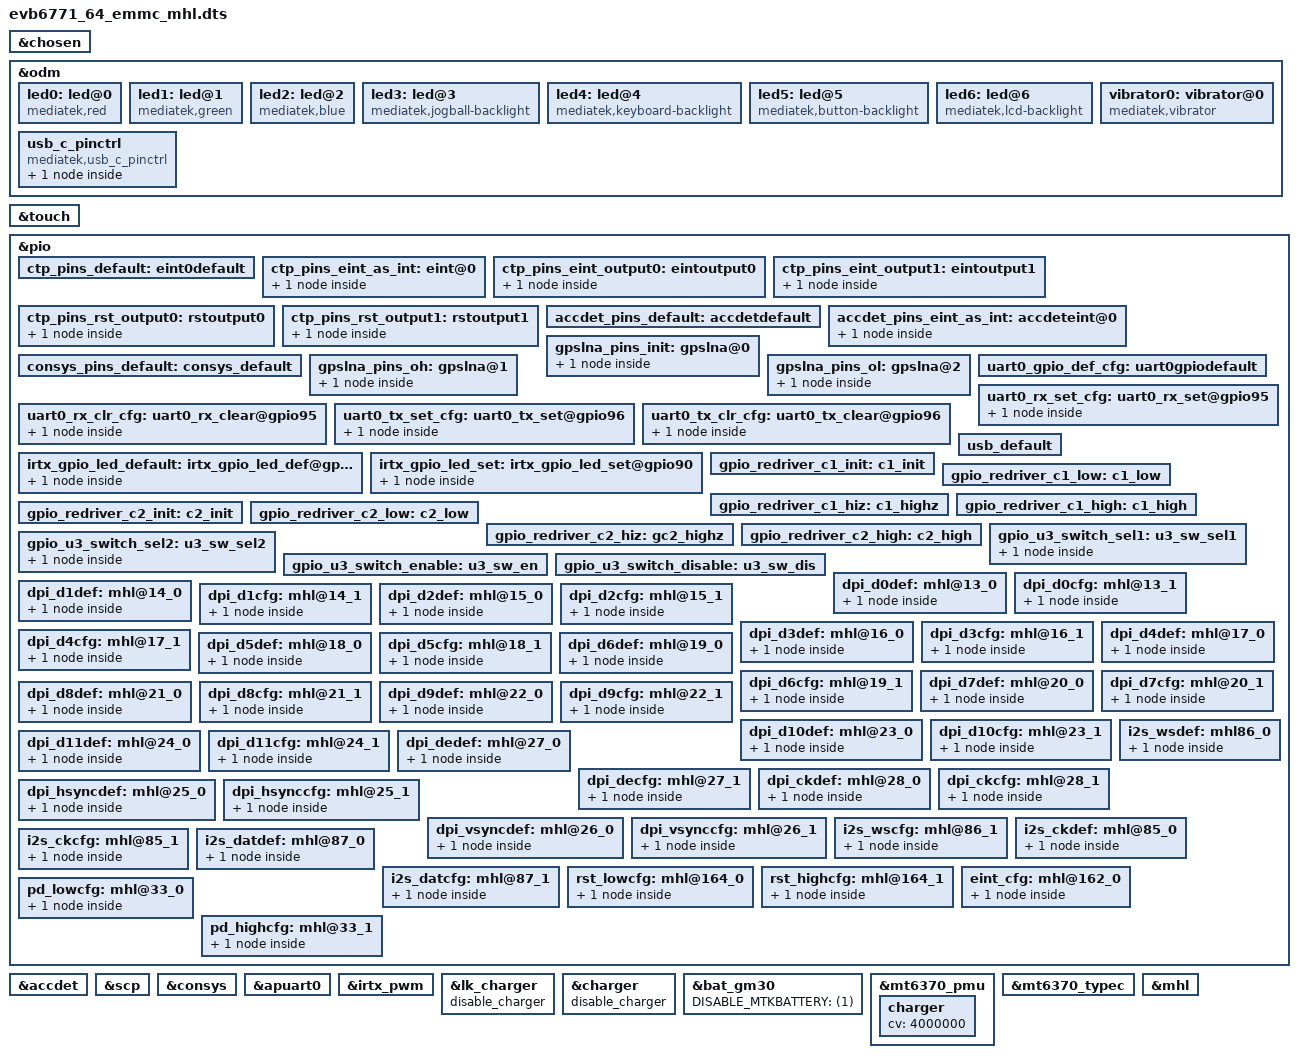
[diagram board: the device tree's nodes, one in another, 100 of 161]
/dts-v1/;
/plugin/;
#include <dt-bindings/interrupt-controller/irq.h>
#include <dt-bindings/interrupt-controller/arm-gic.h>
#include <dt-bindings/pinctrl/mt6771-pinfunc.h>

/* chosen */
&chosen {
	bootargs = "console=tty0 console=ttyMT0,921600n1 root=/dev/ram \
initrd=0x55000000,0x3000000 loglevel=8 \
androidboot.selinux=permissive androidboot.hardware=mt6771 \
initcall_debug=1";
	/* fpga may has no lk, we need to specify display info here */
	/* fb buffer is reserved using this dts by memory node above */

	atag,videolfb-fb_base_l = <0x5e605000>;
	atag,videolfb-fb_base_h = <0x0>;
	atag,videolfb-islcmfound = <1>;
	atag,videolfb-islcm_inited = <0>;
	atag,videolfb-fps= <6000>;
	atag,videolfb-vramSize= <0x017bb000>;
	atag,videolfb-lcmname= "nt35595_fhd_dsi_cmd_truly_nt50358_drv";
};

&odm {
	led0:led@0 {
		compatible = "mediatek,red";
		led_mode = <0>;
		data = <1>;
		pwm_config = <0 0 0 0 0>;
	};
	led1:led@1 {
		compatible = "mediatek,green";
		led_mode = <0>;
		data = <1>;
		pwm_config = <0 0 0 0 0>;
	};
	led2:led@2 {
		compatible = "mediatek,blue";
		led_mode = <0>;
		data = <1>;
		pwm_config = <0 0 0 0 0>;
	};
	led3:led@3 {
		compatible = "mediatek,jogball-backlight";
		led_mode = <0>;
		data = <1>;
		pwm_config = <0 0 0 0 0>;
	};
	led4:led@4 {
		compatible = "mediatek,keyboard-backlight";
		led_mode = <0>;
		data = <1>;
		pwm_config = <0 0 0 0 0>;
	};
	led5:led@5 {
		compatible = "mediatek,button-backlight";
		led_mode = <0>;
		data = <1>;
		pwm_config = <0 0 0 0 0>;
	};
	led6:led@6 {
		compatible = "mediatek,lcd-backlight";
		led_mode = <5>;
		data = <1>;
		pwm_config = <0 1 0 0 0>;
	};
	vibrator0:vibrator@0 {
		compatible = "mediatek,vibrator";
		vib_timer = <25>;
		vib_limit = <9>;
		vib_vol= <9>;
	};

	usb_c_pinctrl:usb_c_pinctrl {
		compatible = "mediatek,usb_c_pinctrl";
	};
};

/* TOUCH start */
&touch {
	tpd-resolution = <1080 1920>;
	use-tpd-button = <0>;
	tpd-key-num = <3>;
	tpd-key-local= <139 172 158 0>;
	tpd-key-dim-local = <90 883 100 40 230 883 100 40 370 883 100 40 0 0 0 0>;
	tpd-max-touch-num = <5>;
	tpd-filter-enable = <1>;
	tpd-filter-pixel-density = <146>;
	tpd-filter-custom-prameters = <0 0 0 0 0 0 0 0 0 0 0 0>;
	tpd-filter-custom-speed = <0 0 0>;
	pinctrl-names = "default", "state_eint_as_int", "state_eint_output0", "state_eint_output1",
		"state_rst_output0", "state_rst_output1";
	pinctrl-0 = <&ctp_pins_default>;
	pinctrl-1 = <&ctp_pins_eint_as_int>;
	pinctrl-2 = <&ctp_pins_eint_output0>;
	pinctrl-3 = <&ctp_pins_eint_output1>;
	pinctrl-4 = <&ctp_pins_rst_output0>;
	pinctrl-5 = <&ctp_pins_rst_output1>;
	status = "okay";
};
&pio {
	ctp_pins_default: eint0default {
	};
	ctp_pins_eint_as_int: eint@0 {
		pins_cmd_dat {
			pins = <PINMUX_GPIO1__FUNC_GPIO1>;
			slew-rate = <0>;
			bias-disable;
		};
	};
	ctp_pins_eint_output0: eintoutput0 {
		pins_cmd_dat {
			pins = <PINMUX_GPIO1__FUNC_GPIO1>;
			slew-rate = <1>;
			output-low;
		};
	};
	ctp_pins_eint_output1: eintoutput1 {
		pins_cmd_dat {
			pins = <PINMUX_GPIO1__FUNC_GPIO1>;
			slew-rate = <1>;
			output-high;
		};
	};
	ctp_pins_rst_output0: rstoutput0 {
		pins_cmd_dat {
			pins = <PINMUX_GPIO2__FUNC_GPIO2>;
			slew-rate = <1>;
			output-low;
		};
	};
	ctp_pins_rst_output1: rstoutput1 {
		pins_cmd_dat {
			pins = <PINMUX_GPIO2__FUNC_GPIO2>;
			slew-rate = <1>;
			output-high;
		};
	};
};
/* TOUCH end */


/* accdet start */
&accdet {
	/* accdet micbias voltage: 0x07,2.7v;0x05,2.5v;0x02,1.9v */
	accdet-mic-vol = <6>;
	headset-mode-setting = <0x500 0x500 1 0x1f0 0x800 0x800 0x20 0x44>;
	accdet-plugout-debounce = <1>;
	/*1:ACC mode, 2:low cost without in bias, 6:low cost with in bias*/
	accdet-mic-mode = <2>;
	/* eint_level_trigger: 8,LEVEL_LOW(default);4,LEVEL_HIGH;others,LEVEL_LOW */
	headset-eint-level-pol = <8>;
	/*0--MD_MAX--UP_MAX--DW_MAX*/
	headset-three-key-threshold = <0 80 220 400>;
	headset-three-key-threshold-CDD = <0 121 192 600>;
	/*0--MD_MAX--VOICE_MAX--UP_MAX--DW_MAX*/
	headset-four-key-threshold = <0 58 121 192 400>;
	/* ACCDET GPIO standardization ACC mode no use */
	pinctrl-names = "default", "state_eint_as_int";
	pinctrl-0 = <&accdet_pins_default>;
	pinctrl-1 = <&accdet_pins_eint_as_int>;
	status = "okay";
};
&pio {
	accdet_pins_default: accdetdefault {
	};
	accdet_pins_eint_as_int: accdeteint@0 {
		pins_cmd_dat {
			/*pins = <PINMUX_GPIO7__FUNC_GPIO7>;*/
			slew-rate = <0>;
			bias-disable;
		};
	};
};
/* accdet end */

&scp {
	core_1 = "enable";
	scp_sramSize = <0x00080000>;     /* scp_A_sram_size */
};

/* CONSYS GPIO standardization */
&pio {
	consys_pins_default: consys_default {
	};
	gpslna_pins_init: gpslna@0 {
		pins_cmd_dat {
			pins = <PINMUX_GPIO155__FUNC_GPIO155>;
			slew-rate = <0>;
			bias-disable;
			output-low;
		};
	};
	gpslna_pins_oh: gpslna@1 {
		pins_cmd_dat {
			pins = <PINMUX_GPIO155__FUNC_GPIO155>;
			slew-rate = <1>;
			output-high;
		};
	};
	gpslna_pins_ol: gpslna@2 {
		pins_cmd_dat {
			pins = <PINMUX_GPIO155__FUNC_GPIO155>;
			slew-rate = <1>;
			output-low;
		};
	};
};
&consys {
	pinctrl-names = "default", "gps_lna_state_init", "gps_lna_state_oh", "gps_lna_state_ol";
	pinctrl-0 = <&consys_pins_default>;
	pinctrl-1 = <&gpslna_pins_init>;
	pinctrl-2 = <&gpslna_pins_oh>;
	pinctrl-3 = <&gpslna_pins_ol>;
	status = "okay";
};
/* CONSYS end */

#if 0
/* CAMERA GPIO standardization */
&pio {
	camera_pins_cam0_rst_0: cam0@0 {
		pins_cmd_dat {
			pins = <PINMUX_GPIO101__FUNC_GPIO101>;
			slew-rate = <1>;
			output-low;
		};
	};
	camera_pins_cam0_rst_1: cam0@1 {
		pins_cmd_dat {
			pins = <PINMUX_GPIO101__FUNC_GPIO101>;
			slew-rate = <1>;
			output-high;
		};
	};
	camera_pins_cam0_pnd_0: cam0@2 {
		pins_cmd_dat {
			pins = <PINMUX_GPIO97__FUNC_GPIO97>;
			slew-rate = <1>;
			output-low;
		};
	};
	camera_pins_cam0_pnd_1: cam0@3 {
		pins_cmd_dat {
			pins = <PINMUX_GPIO97__FUNC_GPIO97>;
			slew-rate = <1>;
			output-high;
		};
	};
	camera_pins_cam1_rst_0: cam1@0 {
		pins_cmd_dat {
			pins = <PINMUX_GPIO102__FUNC_GPIO102>;
			slew-rate = <1>; /*direction 0:in, 1:out*/
			output-low;/*direction out used only. output_low or high*/
		};
	};
	camera_pins_cam1_rst_1: cam1@1 {
		pins_cmd_dat {
			pins = <PINMUX_GPIO102__FUNC_GPIO102>;
			slew-rate = <1>;
			output-high;
		};
	};
	camera_pins_cam1_pnd_0: cam1@2 {
		pins_cmd_dat {
			pins = <PINMUX_GPIO98__FUNC_GPIO98>;
			slew-rate = <1>;
			output-low;
		};
	};
	camera_pins_cam1_pnd_1: cam1@3 {
		pins_cmd_dat {
			pins = <PINMUX_GPIO98__FUNC_GPIO98>;
			slew-rate = <1>;
			output-high;
		};
	};
	camera_pins_cam2_rst_0: cam2@0 {
		pins_cmd_dat {
			pins = <PINMUX_GPIO109__FUNC_GPIO109>;
			slew-rate = <1>;
			output-low;
		};
	};
	camera_pins_cam2_rst_1: cam2@1 {
		pins_cmd_dat {
			pins = <PINMUX_GPIO109__FUNC_GPIO109>;
			slew-rate = <1>;
			output-high;
		};
	};
	camera_pins_cam2_pnd_0: cam2@3 {
		pins_cmd_dat {
			pins = <PINMUX_GPIO107__FUNC_GPIO107>;
			slew-rate = <1>;
			output-low;
		};
	};
	camera_pins_cam2_pnd_1: cam2@4 {
		pins_cmd_dat {
			pins = <PINMUX_GPIO107__FUNC_GPIO107>;
			slew-rate = <1>;
			output-high;
		};
	};
	camera_pins_cam0_vcamd_0: cam0@vcam0 {
		pins_cmd_dat {
			pins = <PINMUX_GPIO91__FUNC_GPIO91>;
			slew-rate = <1>;
			output-low;
		};
	};
	camera_pins_cam0_vcamd_1: cam0@vcam1 {
		pins_cmd_dat {
			pins = <PINMUX_GPIO91__FUNC_GPIO91>;
			slew-rate = <1>;
			output-high;
		};
	};
	camera_pins_cam2_vcamd_0: cam2@vcam0 {
		pins_cmd_dat {
			pins = <PINMUX_GPIO169__FUNC_GPIO169>;
			slew-rate = <1>;
			output-low;
		};
	};
	camera_pins_cam2_vcamd_1: cam1@vcam1 {
		pins_cmd_dat {
			pins = <PINMUX_GPIO169__FUNC_GPIO169>;
			slew-rate = <1>;
			output-high;
		};
	};
	camera_pins_cam2_vcama_0: cam1@vcam2 {
		pins_cmd_dat {
			pins = <PINMUX_GPIO169__FUNC_GPIO169>;
			slew-rate = <1>;
			output-low;
		};
	};
	camera_pins_cam2_vcama_1: cam1@vcam3 {
		pins_cmd_dat {
			pins = <PINMUX_GPIO169__FUNC_GPIO169>;
			slew-rate = <1>;
			output-high;
		};
	};
	camera_pins_cam0_mclk_on: camera_pins_cam0_mclk_on {
		pins_cmd_dat {
			pins = <PINMUX_GPIO99__FUNC_CMMCLK0>;
		};
	};
	camera_pins_cam0_mclk_off: camera_pins_cam0_mclk_off {
		pins_cmd_dat {
			pins = <PINMUX_GPIO99__FUNC_GPIO99>;
		};
	};
	camera_pins_cam1_mclk_off: camera_pins_cam1_mclk_off {
		pins_cmd_dat {
			pins = <PINMUX_GPIO100__FUNC_GPIO100>;
		};
	};
	camera_pins_cam1_mclk_on: camera_pins_cam1_mclk_on {
		pins_cmd_dat {
			pins = <PINMUX_GPIO100__FUNC_CMMCLK1>;
		};
	};
	camera_pins_cam2_mclk_off: camera_pins_cam2_mclk_off {
		pins_cmd_dat {
			pins = <PINMUX_GPIO108__FUNC_GPIO108>;
		};
	};
	camera_pins_cam2_mclk_on: camera_pins_cam2_mclk_on {
		pins_cmd_dat {
			pins = <PINMUX_GPIO108__FUNC_CMMCLK2>;
		};
	};
	camera_pins_default: camdefault {
	};
};
&kd_camera_hw1 {
	pinctrl-names = "default",
			"cam0_rst0", "cam0_rst1",
			"cam0_pnd0", "cam0_pnd1",
			"cam1_rst0", "cam1_rst1",
			"cam1_pnd0", "cam1_pnd1",
			"cam2_rst0", "cam2_rst1",
			"cam2_pnd0", "cam2_pnd1",
			"cam_ldo_vcamd_0", "cam_ldo_vcamd_1",
			"cam_ldo_main2_vcamd_0", "cam_ldo_main2_vcamd_1",
			"cam_ldo_main2_vcama_0", "cam_ldo_main2_vcama_1",
			"cam0_mclk_off", "cam0_mclk_on",
			"cam1_mclk_off", "cam1_mclk_on",
			"cam2_mclk_off", "cam2_mclk_on";
	pinctrl-0 = <&camera_pins_default>;
	pinctrl-1 = <&camera_pins_cam0_rst_0>;
	pinctrl-2 = <&camera_pins_cam0_rst_1>;
	pinctrl-3 = <&camera_pins_cam0_pnd_0>;
	pinctrl-4 = <&camera_pins_cam0_pnd_1>;
	pinctrl-5 = <&camera_pins_cam1_rst_0>;
	pinctrl-6 = <&camera_pins_cam1_rst_1>;
	pinctrl-7 = <&camera_pins_cam1_pnd_0>;
	pinctrl-8 = <&camera_pins_cam1_pnd_1>;
	pinctrl-9 = <&camera_pins_cam2_rst_0>;
	pinctrl-10 = <&camera_pins_cam2_rst_1>;
	pinctrl-11 = <&camera_pins_cam2_pnd_0>;
	pinctrl-12 = <&camera_pins_cam2_pnd_1>;
	pinctrl-13 = <&camera_pins_cam0_vcamd_0>;
	pinctrl-14 = <&camera_pins_cam0_vcamd_1>;
	pinctrl-15 = <&camera_pins_cam2_vcamd_0>;
	pinctrl-16 = <&camera_pins_cam2_vcamd_1>;
	pinctrl-17 = <&camera_pins_cam2_vcama_0>;
	pinctrl-18 = <&camera_pins_cam2_vcama_1>;
	pinctrl-19 = <&camera_pins_cam0_mclk_off>;
	pinctrl-20 = <&camera_pins_cam0_mclk_on>;
	pinctrl-21 = <&camera_pins_cam1_mclk_off>;
	pinctrl-22 = <&camera_pins_cam1_mclk_on>;
	pinctrl-23 = <&camera_pins_cam2_mclk_off>;
	pinctrl-24 = <&camera_pins_cam2_mclk_on>;

	status = "okay";
};
#endif

/* UART GPIO */
&apuart0 {
	pinctrl-names = "uart0_gpio_default",
			"uart0_rx_set",
			"uart0_rx_clear",
			"uart0_tx_set",
			"uart0_tx_clear";
	pinctrl-0 = <&uart0_gpio_def_cfg>;
	pinctrl-1 = <&uart0_rx_set_cfg>;
	pinctrl-2 = <&uart0_rx_clr_cfg>;
	pinctrl-3 = <&uart0_tx_set_cfg>;
	pinctrl-4 = <&uart0_tx_clr_cfg>;
	status = "okay";
};

&pio {
	/* UART GPIO Settings - Start */
	/* UART0: rx set, rx clear, tx clear, tx clear*/
	uart0_gpio_def_cfg:uart0gpiodefault {

	};
	uart0_rx_set_cfg:uart0_rx_set@gpio95 {
		pins_cmd_dat {
			pins = <PINMUX_GPIO95__FUNC_URXD0>;
		};
	};
	uart0_rx_clr_cfg:uart0_rx_clear@gpio95 {
		pins_cmd_dat {
			pins = <PINMUX_GPIO95__FUNC_GPIO95>;
			slew-rate = <1>;
			output-high;
		};
	};
	uart0_tx_set_cfg:uart0_tx_set@gpio96 {
		pins_cmd_dat {
			pins = <PINMUX_GPIO96__FUNC_UTXD0>;
		};
	};
	uart0_tx_clr_cfg:uart0_tx_clear@gpio96 {
		pins_cmd_dat {
			pins = <PINMUX_GPIO96__FUNC_GPIO96>;
			slew-rate = <1>;
			output-high;
		};
	};
};/* UART GPIO end */

/* IRTX GPIO Start */
&irtx_pwm {
	pinctrl-names = "irtx_gpio_led_default", "irtx_gpio_led_set";
	pinctrl-0 = <&irtx_gpio_led_default>;
	pinctrl-1 = <&irtx_gpio_led_set>;
	status = "okay";
};
&pio {
	/* IRTX GPIO Settings -Start */
	/* default: GPIO0, output, high */
	irtx_gpio_led_default:irtx_gpio_led_def@gpio90 {
		pins_cmd_dat {
			pins = <PINMUX_GPIO90__FUNC_GPIO90>;
			slew-rate = <1>;
			bias-disable;
			output-low;
			input-schmitt-enable = <0>;
		};
	};

	irtx_gpio_led_set:irtx_gpio_led_set@gpio90 {
		pins_cmd_dat {
			pins = <PINMUX_GPIO90__FUNC_PWM_A>;
			slew-rate = <1>;
			output-high;
		};
	};
}; /* IRTX GPIO Settings -End */

&lk_charger {
	disable_charger;
};

&charger {
	disable_charger;
};

&bat_gm30 {
	DISABLE_MTKBATTERY = <(1)>;
};

&mt6370_pmu {
	mt6370,intr_gpio_num = <10>; /* direct defined GPIO num */
	mt6370,intr_gpio = <&pio 10 0x0>;
	charger {
		cv = <4000000>;		/* uA */
	};
};

&mt6370_typec {
	mt6370pd,intr_gpio_num = <41>; /* direct defined GPIO num */
	mt6370pd,intr_gpio = <&pio 41 0x0>;
};

/* USB TYPEC GPIO start */
&pio {
	usb_default: usb_default {
	};

	gpio_redriver_c1_init: c1_init {
	};

	gpio_redriver_c1_low: c1_low {
	};

	gpio_redriver_c1_hiz: c1_highz {
	};

	gpio_redriver_c1_high: c1_high {
	};

	gpio_redriver_c2_init: c2_init {
	};

	gpio_redriver_c2_low: c2_low {
	};

	gpio_redriver_c2_hiz: gc2_highz {
	};

	gpio_redriver_c2_high: c2_high {
	};

	gpio_u3_switch_sel1: u3_sw_sel1 {
		pins_cmd_dat {
			pins = <PINMUX_GPIO177__FUNC_GPIO177>;
			slew-rate = <1>;
			output-low;
		};
	};

	gpio_u3_switch_sel2: u3_sw_sel2 {
		pins_cmd_dat {
			pins = <PINMUX_GPIO177__FUNC_GPIO177>;
			slew-rate = <1>;
			output-high;
		};
	};

	gpio_u3_switch_enable: u3_sw_en {
	};

	gpio_u3_switch_disable: u3_sw_dis {
	};
};

&usb_c_pinctrl {
	pinctrl-names = "usb_default",
		"redriver_c1_init",
		"redriver_c1_low",
		"redriver_c1_hiz",
		"redriver_c1_high",
		"redriver_c2_init",
		"redriver_c2_low",
		"redriver_c2_hiz",
		"redriver_c2_high",
		"u3_switch_sel1",
		"u3_switch_sel2",
		"u3_switch_enable",
		"u3_switch_disable";

	pinctrl-0 = <&usb_default>;
	pinctrl-1 = <&gpio_redriver_c1_init>;
	pinctrl-2 = <&gpio_redriver_c1_low>;
	pinctrl-3 = <&gpio_redriver_c1_hiz>;
	pinctrl-4 = <&gpio_redriver_c1_high>;
	pinctrl-5 = <&gpio_redriver_c2_init>;
	pinctrl-6 = <&gpio_redriver_c2_low>;
	pinctrl-7 = <&gpio_redriver_c2_hiz>;
	pinctrl-8 = <&gpio_redriver_c2_high>;
	pinctrl-9 = <&gpio_u3_switch_sel1>;
	pinctrl-10 = <&gpio_u3_switch_sel2>;
	pinctrl-11 = <&gpio_u3_switch_enable>;
	pinctrl-12 = <&gpio_u3_switch_disable>;
	status = "okay";

	usb_switch-data {
		en_pin_num = <0>;
		en_pin_val = <0>; /*DISABLE=0 ENABLE=1*/
		sel_pin_num = <177>;
		sel_pin_val = <1>; /*CC1=1, CC2=2*/
		c1_pin_num = <0>;
		c1_pin_val = <0>; /*Low=0, HighZ=1, High=2*/
		c2_pin_num = <0>;
		c2_pin_val = <0>;
	};
};

/* USB TYPEC GPIO end */

/* MHL GPIO define start */
&pio {

	dpi_d0def: mhl@13_0 {
		pins_cmd_dat {
			pins = <PINMUX_GPIO13__FUNC_GPIO13>;
			slew-rate = <0>;
			bias-pull-down = <11>;
		};
	};
	dpi_d0cfg: mhl@13_1 {
		pins_cmd_dat {
			pins = <PINMUX_GPIO13__FUNC_DBPI_D0>;
		};
	};

	dpi_d1def: mhl@14_0 {
		pins_cmd_dat {
			pins = <PINMUX_GPIO14__FUNC_GPIO14>;
			slew-rate = <0>;
			bias-pull-down = <11>;
		};
	};
	dpi_d1cfg: mhl@14_1 {
		pins_cmd_dat {
			pins = <PINMUX_GPIO14__FUNC_DBPI_D1>;
		};
	};

	dpi_d2def: mhl@15_0 {
		pins_cmd_dat {
			pins = <PINMUX_GPIO15__FUNC_GPIO15>;
			slew-rate = <0>;
			bias-pull-down = <11>;
		};
	};
	dpi_d2cfg: mhl@15_1 {
		pins_cmd_dat {
			pins = <PINMUX_GPIO15__FUNC_DBPI_D2>;
		};
	};

	dpi_d3def: mhl@16_0 {
		pins_cmd_dat {
			pins = <PINMUX_GPIO16__FUNC_GPIO16>;
			slew-rate = <0>;
			bias-pull-down = <11>;
		};
	};
	dpi_d3cfg: mhl@16_1 {
		pins_cmd_dat {
			pins = <PINMUX_GPIO16__FUNC_DBPI_D3>;
		};
	};

	dpi_d4def: mhl@17_0 {
		pins_cmd_dat {
			pins = <PINMUX_GPIO17__FUNC_GPIO17>;
			slew-rate = <0>;
			bias-pull-down = <11>;
		};
	};
	dpi_d4cfg: mhl@17_1 {
		pins_cmd_dat {
			pins = <PINMUX_GPIO17__FUNC_DBPI_D4>;
		};
	};

	dpi_d5def: mhl@18_0 {
		pins_cmd_dat {
			pins = <PINMUX_GPIO18__FUNC_GPIO18>;
			slew-rate = <0>;
			bias-pull-down = <11>;
		};
	};
	dpi_d5cfg: mhl@18_1 {
		pins_cmd_dat {
			pins = <PINMUX_GPIO18__FUNC_DBPI_D5>;
		};
	};

	dpi_d6def: mhl@19_0 {
		pins_cmd_dat {
			pins = <PINMUX_GPIO19__FUNC_GPIO19>;
			slew-rate = <0>;
			bias-pull-down = <11>;
		};
	};
	dpi_d6cfg: mhl@19_1 {
		pins_cmd_dat {
			pins = <PINMUX_GPIO19__FUNC_DBPI_D6>;
		};
	};

	dpi_d7def: mhl@20_0 {
		pins_cmd_dat {
			pins = <PINMUX_GPIO20__FUNC_GPIO20>;
			slew-rate = <0>;
			bias-pull-down = <11>;
		};
	};
	dpi_d7cfg: mhl@20_1 {
		pins_cmd_dat {
			pins = <PINMUX_GPIO20__FUNC_DBPI_D7>;
		};
	};

	dpi_d8def: mhl@21_0 {
		pins_cmd_dat {
			pins = <PINMUX_GPIO21__FUNC_GPIO21>;
			slew-rate = <0>;
			bias-pull-down = <11>;
		};
	};
	dpi_d8cfg: mhl@21_1 {
		pins_cmd_dat {
			pins = <PINMUX_GPIO21__FUNC_DBPI_D8>;
		};
	};

	dpi_d9def: mhl@22_0 {
		pins_cmd_dat {
			pins = <PINMUX_GPIO22__FUNC_GPIO22>;
			slew-rate = <0>;
			bias-pull-down = <11>;
		};
	};
	dpi_d9cfg: mhl@22_1 {
		pins_cmd_dat {
			pins = <PINMUX_GPIO22__FUNC_DBPI_D9>;
		};
	};

	dpi_d10def: mhl@23_0 {
		pins_cmd_dat {
			pins = <PINMUX_GPIO23__FUNC_GPIO23>;
			slew-rate = <0>;
			bias-pull-down = <11>;
		};
	};
	dpi_d10cfg: mhl@23_1 {
		pins_cmd_dat {
			pins = <PINMUX_GPIO23__FUNC_DBPI_D10>;
		};
	};

	dpi_d11def: mhl@24_0 {
		pins_cmd_dat {
			pins = <PINMUX_GPIO24__FUNC_GPIO24>;
			slew-rate = <0>;
			bias-pull-down = <11>;
		};
	};
	dpi_d11cfg: mhl@24_1 {
		pins_cmd_dat {
			pins = <PINMUX_GPIO24__FUNC_DBPI_D11>;
		};
	};
	dpi_dedef: mhl@27_0 {
		pins_cmd_dat {
			pins = <PINMUX_GPIO27__FUNC_GPIO27>;
			slew-rate = <0>;
			bias-pull-down = <11>;
		};
	};
	dpi_decfg: mhl@27_1 {
		pins_cmd_dat {
			pins = <PINMUX_GPIO27__FUNC_DBPI_DE>;
		};
	};
	dpi_ckdef: mhl@28_0 {
		pins_cmd_dat {
			pins = <PINMUX_GPIO28__FUNC_GPIO28>;
			slew-rate = <0>;
			bias-pull-down = <11>;
		};
	};
	dpi_ckcfg: mhl@28_1 {
		pins_cmd_dat {
			pins = <PINMUX_GPIO28__FUNC_DBPI_CK>;
		};
	};
	dpi_hsyncdef: mhl@25_0 {
		pins_cmd_dat {
			pins = <PINMUX_GPIO25__FUNC_GPIO25>;
			slew-rate = <0>;
			bias-pull-down = <11>;
		};
	};
	dpi_hsynccfg: mhl@25_1 {
		pins_cmd_dat {
			pins = <PINMUX_GPIO25__FUNC_DBPI_HSYNC>;
		};
	};

	dpi_vsyncdef: mhl@26_0 {
		pins_cmd_dat {
			pins = <PINMUX_GPIO26__FUNC_GPIO26>;
			slew-rate = <0>;
			bias-pull-down = <11>;
		};
	};
	dpi_vsynccfg: mhl@26_1 {
		pins_cmd_dat {
			pins = <PINMUX_GPIO26__FUNC_DBPI_VSYNC>;
		};
	};
	i2s_wsdef: mhl86_0 {
		pins_cmd_dat {
			pins = <PINMUX_GPIO86__FUNC_GPIO86>;
			slew-rate = <0>;
			bias-pull-down = <11>;
/*			drive-strength = <1>;	*/
		};
	};
	i2s_wscfg: mhl@86_1 {
		pins_cmd_dat {
			pins = <PINMUX_GPIO86__FUNC_I2S1_LRCK>;
/*			drive-strength = <0>;	*/
		};
	};

	i2s_ckdef: mhl@85_0 {
		pins_cmd_dat {
			pins = <PINMUX_GPIO85__FUNC_GPIO85>;
			slew-rate = <0>;
			bias-pull-down = <11>;
/*			drive-strength = <1>;	*/
		};
	};
	i2s_ckcfg: mhl@85_1 {
		pins_cmd_dat {
			pins = <PINMUX_GPIO85__FUNC_I2S1_BCK>;
/*			drive-strength = <0>;	*/
		};
	};
	i2s_datdef: mhl@87_0 {
		pins_cmd_dat {
			pins = <PINMUX_GPIO87__FUNC_GPIO87>;
			slew-rate = <0>;
			bias-pull-down = <11>;
/*			drive-strength = <1>;	*/
		};
	};
	i2s_datcfg: mhl@87_1 {
		pins_cmd_dat {
			pins = <PINMUX_GPIO87__FUNC_I2S1_DO>;
/*			drive-strength = <0>;	*/
		};
	};
	rst_lowcfg: mhl@164_0 {
		pins_cmd_dat {
			pins = <PINMUX_GPIO164__FUNC_GPIO164>;
			slew-rate = <1>;
			output-low;
		};
	};
	rst_highcfg: mhl@164_1 {
		pins_cmd_dat {
			pins = <PINMUX_GPIO164__FUNC_GPIO164>;
			slew-rate = <1>;
			output-high;
		};
	};
	eint_cfg: mhl@162_0 {
		pins_cmd_dat {
			pins = <PINMUX_GPIO162__FUNC_GPIO162>;
			slew-rate = <0>;
			bias-pull-up = <11>;
		};
	};
	pd_lowcfg: mhl@33_0 {
		pins_cmd_dat {
			pins = <PINMUX_GPIO33__FUNC_GPIO33>;
			slew-rate = <1>;
			output-low;
		};
	};
	pd_highcfg: mhl@33_1 {
		pins_cmd_dat {
			pins = <PINMUX_GPIO33__FUNC_GPIO33>;
			slew-rate = <1>;
			output-high;
		};
	};
};

&mhl {
	pinctrl-names = "dpi_d0_def", "dpi_d0_cfg",
	"dpi_d1_def", "dpi_d1_cfg", "dpi_d2_def", "dpi_d2_cfg",
	"dpi_d3_def", "dpi_d3_cfg", "dpi_d4_def", "dpi_d4_cfg",
	"dpi_d5_def", "dpi_d5_cfg", "dpi_d6_def", "dpi_d6_cfg",
	"dpi_d7_def", "dpi_d7_cfg", "dpi_d8_def", "dpi_d8_cfg",
	"dpi_d9_def", "dpi_d9_cfg", "dpi_d10_def", "dpi_d10_cfg",
	"dpi_d11_def", "dpi_d11_cfg", "dpi_ck_def", "dpi_ck_cfg",
	"dpi_de_def", "dpi_de_cfg", "dpi_hsync_def", "dpi_hsync_cfg",
	"dpi_vsync_def", "dpi_vsync_cfg", "i2s_dat_def", "i2s_dat_cfg",
	"i2s_ws_def", "i2s_ws_cfg", "i2s_ck_def", "i2s_ck_cfg",
	"rst_low_cfg", "rst_high_cfg", "eint_input_cfg",
	"pd_low_cfg", "pd_high_cfg";
	pinctrl-0 = <&dpi_d0def>;
	pinctrl-1 = <&dpi_d0cfg>;
	pinctrl-2 = <&dpi_d1def>;
	pinctrl-3 = <&dpi_d1cfg>;
	pinctrl-4 = <&dpi_d2def>;
	pinctrl-5 = <&dpi_d2cfg>;
	pinctrl-6 = <&dpi_d3def>;
	pinctrl-7 = <&dpi_d3cfg>;
	pinctrl-8 = <&dpi_d4def>;
	pinctrl-9 = <&dpi_d4cfg>;
	pinctrl-10 = <&dpi_d5def>;
	pinctrl-11 = <&dpi_d5cfg>;
	pinctrl-12 = <&dpi_d6def>;
	pinctrl-13 = <&dpi_d6cfg>;
	pinctrl-14 = <&dpi_d7def>;
	pinctrl-15 = <&dpi_d7cfg>;
	pinctrl-16 = <&dpi_d8def>;
	pinctrl-17 = <&dpi_d8cfg>;
	pinctrl-18 = <&dpi_d9def>;
	pinctrl-19 = <&dpi_d9cfg>;
	pinctrl-20 = <&dpi_d10def>;
	pinctrl-21 = <&dpi_d10cfg>;
	pinctrl-22 = <&dpi_d11def>;
	pinctrl-23 = <&dpi_d11cfg>;
	pinctrl-24 = <&dpi_ckdef>;
	pinctrl-25 = <&dpi_ckcfg>;
	pinctrl-26 = <&dpi_dedef>;
	pinctrl-27 = <&dpi_decfg>;
	pinctrl-28 = <&dpi_hsyncdef>;
	pinctrl-29 = <&dpi_hsynccfg>;
	pinctrl-30 = <&dpi_vsyncdef>;
	pinctrl-31 = <&dpi_vsynccfg>;
	pinctrl-32 = <&i2s_datdef>;
	pinctrl-33 = <&i2s_datcfg>;
	pinctrl-34 = <&i2s_wsdef>;
	pinctrl-35 = <&i2s_wscfg>;
	pinctrl-36 = <&i2s_ckdef>;
	pinctrl-37 = <&i2s_ckcfg>;
	pinctrl-38 = <&rst_lowcfg>;
	pinctrl-39 = <&rst_highcfg>;
	pinctrl-40 = <&eint_cfg>;
	pinctrl-41 = <&pd_lowcfg>;
	pinctrl-42 = <&pd_highcfg>;
	status = "okay";
};
/* MHL GPIO define end */

#include <evb6771_64_emmc/cust.dtsi>
/*End of this file, DO NOT ADD ANYTHING HERE*/
